# M061 register map
File version: 2.0.2.1
TOSHIBA Cortex-M0 MCU
CPU: 
Registers are 32-bit, read-write, reset 0x0 unless marked. A register's access mark holds for its fields unless they carry their own. Offsets are from the block's base; lines under a group give offsets from that group; [hi:lo] are bit positions; {n}, {i} and the like mark numbered series; 'fields as' and 'values as' point back to an identical list; <NAME> marks a mode.

## Memory map
0x4005D000 TEMP size 0x8 — Temperature Sensor
0x4006E000 LCD size 0x5C — LCD Driver (LCD)
0x4008D000 T16A0 size 0x14 — 16-bit TimerA
0x4008E000 T16A1 size 0x14 — 16-bit TimerA
0x4008F000 T16A2 size 0x14 — 16-bit TimerA
0x40090000 T16A3 size 0x14 — 16-bit TimerA
0x40091000 T16A4 size 0x14 — 16-bit TimerA
0x400C0000 PA size 0xC — General Purpose Input_Output Port (PA)
0x400C0100 PB size 0xC — General Purpose Input_Output Port (PB)
0x400C0200 PC size 0xC — General Purpose Input_Output Port (PC)
0x400C0300 PD size 0xC — General Purpose Input_Output Port (PD)
0x400C0400 PE size 0x14 — General Purpose Input_Output Port (PE)
0x400C0500 PF size 0xC — General Purpose Input_Output Port (PF)
0x400C0600 PG size 0x10 — General Purpose Input_Output Port (PG)
0x400C0700 PH size 0x14 — General Purpose Input_Output Port (PH)
0x400C0800 PI size 0x14 — General Purpose Input_Output Port (PI)
0x400C0900 PJ size 0x10 — General Purpose Input_Output Port (PJ)
0x400C0A00 PK size 0xC — General Purpose Input_Output Port (PK)
0x400C4000 TB0 size 0x30 — 16-bit Timer_Event Counter (TB)
0x400CC000 RTC size 0x3 — Real Time Clock (RTC)
0x400E0000 SBI size 0x18 — Serial Bus Interface (SBI)
0x400E1000 SC0 size 0x20 — Serial Channel (SC)
0x400E1100 SC1 size 0x20 — Serial Channel (SC)
0x400E1200 SC2 size 0x20 — Serial Channel (SC)
0x400E1300 SC3 size 0x20 — Serial Channel (SC)
0x400F2000 WD0 size 0x8 — Watchdog Timer (WD)
0x400F3000 CG size 0x18 — Clock Generator (CG)
0x400F4000 LVD — Low Voltage detector control register
0x400FC000 AD size 0x1C — Analog-to-Digital Converter (AD)
0x41FFF000 FC — Flash Control (FC)
0x44067000 DSAD0 size 0x24 — 16-bit Deita sigma AD converter
0x44068000 DSAD1 size 0x24 — 16-bit Deita sigma AD converter
0x44069000 DSAD2 size 0x24 — 16-bit Deita sigma AD converter
0x4406F000 PCE size 0x14 — Power Calculation Engine (PCE)
0x44092000 T16A5 size 0x14 — 16-bit TimerA
0x44093000 T16A6 size 0x14 — 16-bit TimerA
0x440C4100 TB1 size 0x30 — 16-bit Timer_Event Counter (TB)
0x440F2100 WD1 size 0x8 — Watchdog Timer (WD)

## PA — General Purpose Input_Output Port (PA)
Base 0x400C0000
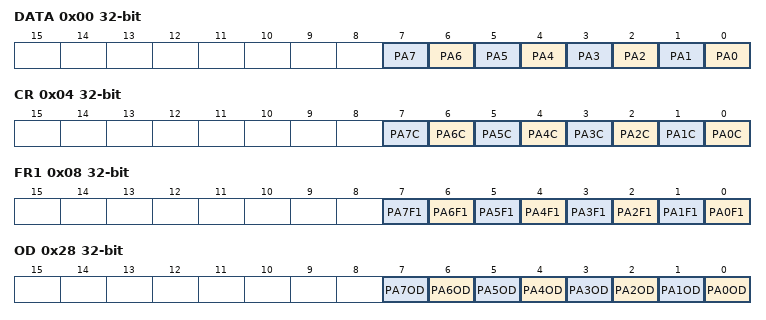
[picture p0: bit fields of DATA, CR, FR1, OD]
0x00 DATA — PA Data Register
  [n] PA{n} (n=0..7)
0x04 CR — PA Control Register
  [n] PA{n}C (n=0..7)
0x08 FR1 — PA Function Register 1
  [n] PA{n}F1 (n=0..7)
0x28 OD — PA Open Drain Control Register
  [n] PA{n}OD (n=0..7)
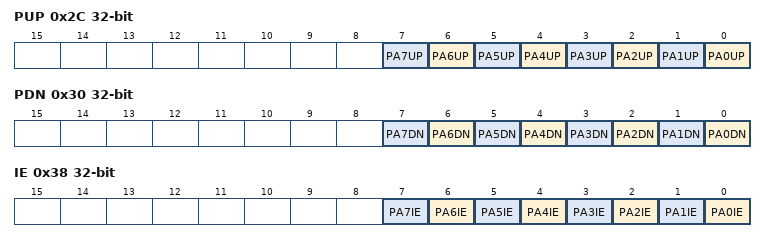
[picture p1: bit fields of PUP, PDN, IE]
0x2C PUP — PA Pull-Up Control Register
  [n] PA{n}UP (n=0..7)
0x30 PDN — PA Pull-Down Control Register
  [n] PA{n}DN (n=0..7)
0x38 IE — PA Input Enable Control Register
  [n] PA{n}IE (n=0..7)

## PB — General Purpose Input_Output Port (PB)
Base 0x400C0100
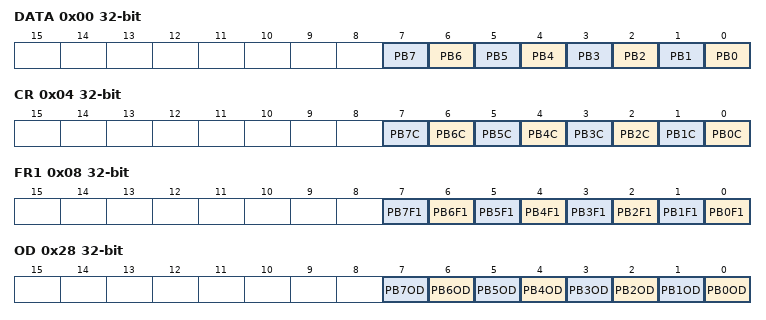
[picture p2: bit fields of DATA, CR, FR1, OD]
0x00 DATA — PB Data Register
  [n] PB{n} (n=0..7)
0x04 CR — PB Control Register
  [n] PB{n}C (n=0..7)
0x08 FR1 — PB Function Register 1
  [n] PB{n}F1 (n=0..7)
0x28 OD — PB Open Drain Control Register
  [n] PB{n}OD (n=0..7)
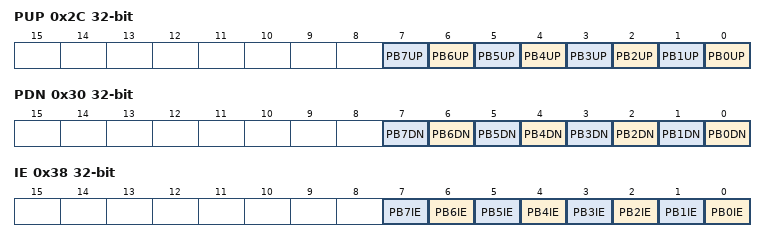
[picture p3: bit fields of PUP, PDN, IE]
0x2C PUP — PB Pull-Up Control Register
  [n] PB{n}UP (n=0..7)
0x30 PDN — PB Pull-Down Control Register
  [n] PB{n}DN (n=0..7)
0x38 IE — PB Input Enable Control Register
  [n] PB{n}IE (n=0..7)

## PC — General Purpose Input_Output Port (PC)
Base 0x400C0200
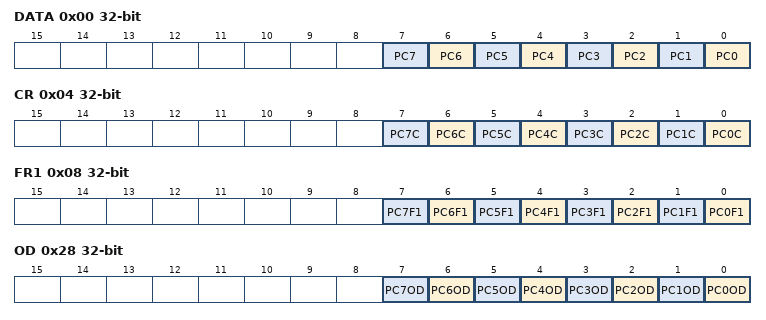
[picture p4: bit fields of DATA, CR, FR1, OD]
0x00 DATA — PC Data Register
  [n] PC{n} (n=0..7)
0x04 CR — PC Control Register
  [n] PC{n}C (n=0..7)
0x08 FR1 — PC Function Register 1
  [n] PC{n}F1 (n=0..7)
0x28 OD — PC Open Drain Control Register
  [n] PC{n}OD (n=0..7)
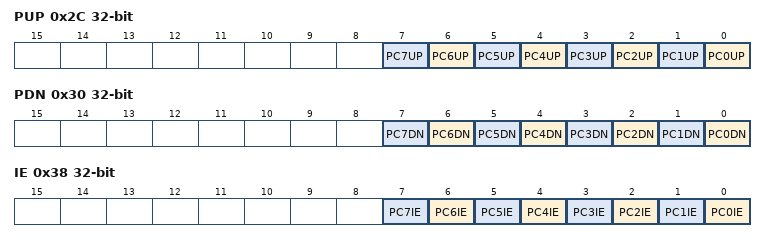
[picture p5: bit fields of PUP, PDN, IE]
0x2C PUP — PC Pull-Up Control Register
  [n] PC{n}UP (n=0..7)
0x30 PDN — PC Pull-Down Control Register
  [n] PC{n}DN (n=0..7)
0x38 IE — PC Input Enable Control Register
  [n] PC{n}IE (n=0..7)

## PD — General Purpose Input_Output Port (PD)
Base 0x400C0300
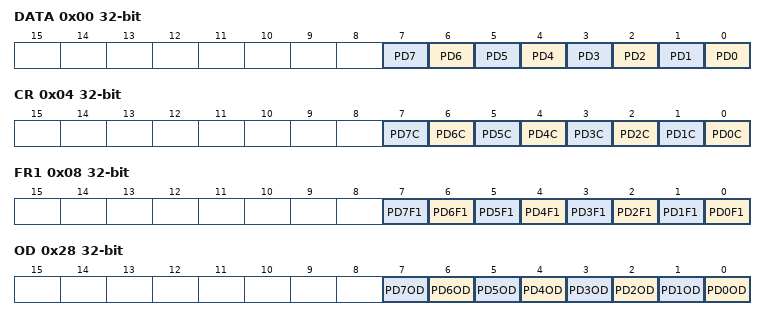
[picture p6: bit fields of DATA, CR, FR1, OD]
0x00 DATA — PD Data Register
  [n] PD{n} (n=0..7)
0x04 CR — PD Control Register
  [n] PD{n}C (n=0..7)
0x08 FR1 — PD Function Register 1
  [n] PD{n}F1 (n=0..7)
0x28 OD — PD Open Drain Control Register
  [n] PD{n}OD (n=0..7)
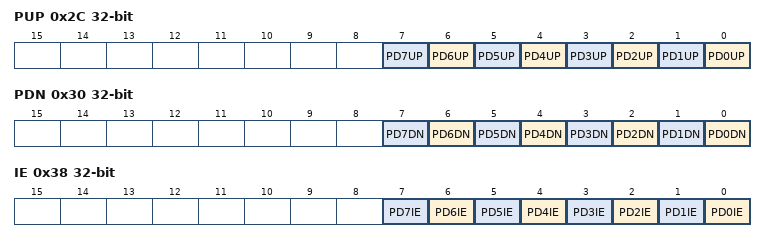
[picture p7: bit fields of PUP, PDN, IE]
0x2C PUP — PD Pull-Up Control Register
  [n] PD{n}UP (n=0..7)
0x30 PDN — PD Pull-Down Control Register
  [n] PD{n}DN (n=0..7)
0x38 IE — PD Input Enable Control Register
  [n] PD{n}IE (n=0..7)
